# PIC32CX1025SG60100 register map
Vendor: Microchip Technology; Series: PIC32CXSG60; File version: 0
CPU: CM4 r0p1, selectable endian, MPU, FPU, 3 interrupt priority bits, 137 interrupts
Registers are 32-bit, read-write, reset 0x0 unless marked. A register's access mark holds for its fields unless they carry their own. Offsets are from the block's base; [hi:lo] are bit positions; {n}, {i} and the like mark numbered series; 'fields as' and 'values as' point back to an identical list.

## FPU — Floating Point Unit
Base 0xE000EF30
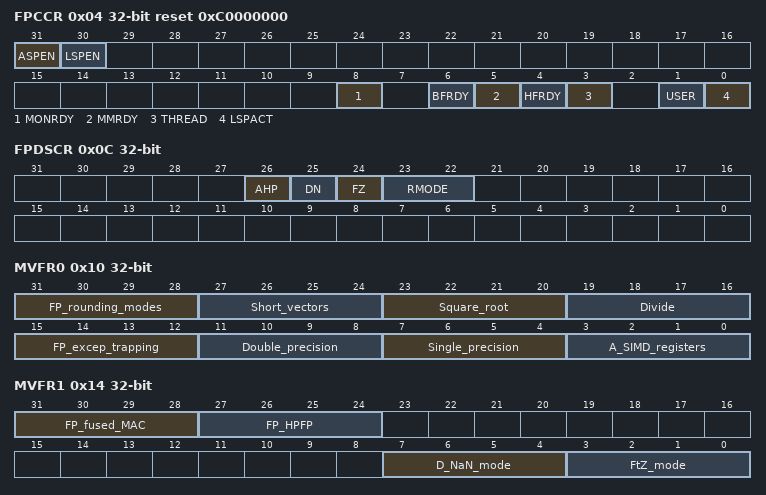
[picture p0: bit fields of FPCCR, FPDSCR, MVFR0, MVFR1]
0x04 FPCCR reset 0xC0000000 — Floating-Point Context Control Register
  [31] ASPEN, [30] LSPEN, [8] MONRDY, [6] BFRDY, [5] MMRDY, [4] HFRDY, [3] THREAD, [1] USER, [0] LSPACT
0x08 FPCAR — Floating-Point Context Address Register
  [31:3] ADDRESS — Address for FP registers in exception stack frame
0x0C FPDSCR — Floating-Point Default Status Control Register
  [26] AHP — Default value for FPSCR.AHP
  [25] DN — Default value for FPSCR.DN
  [24] FZ — Default value for FPSCR.FZ
  [23:22] RMODE — Default value for FPSCR.RMODE
    0=RN (Round to Nearest); 1=RP (Round towards Positive Infinity); 2=RM (Round towards Negative Infinity); 3=RZ (Round towards Zero)
0x10 MVFR0 ro — Media and FP Feature Register 0
  [31:28] FP_rounding_modes, [27:24] Short_vectors, [23:20] Square_root, [19:16] Divide, [15:12] FP_excep_trapping, [11:8] Double_precision, [7:4] Single_precision, [3:0] A_SIMD_registers
0x14 MVFR1 ro — Media and FP Feature Register 1
  [31:28] FP_fused_MAC, [27:24] FP_HPFP, [7:4] D_NaN_mode, [3:0] FtZ_mode

## ITM — Instrumentation Trace Macrocell
Base 0xE0000000
{0x0+4i} PORT_BYTE_MODE[{i}] (i=0..31) wo — ITM Stimulus Port Registers
  [7:0] PORT
{0x0+4i} PORT_HWORD_MODE[{i}] (i=0..31) wo (alternate view of PORT_BYTE_MODE[{i}]) — ITM Stimulus Port Registers
  [15:0] PORT
{0x0+4i} PORT_WORD_MODE[{i}] (i=0..31) wo (alternate view of PORT_BYTE_MODE[{i}]) — ITM Stimulus Port Registers
  [31:0] PORT
0xE00 TER — ITM Trace Enable Register
0xE40 TPR — ITM Trace Privilege Register
  [3:0] PRIVMASK
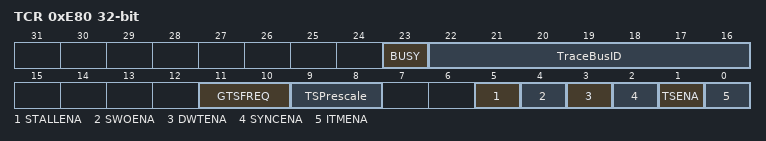
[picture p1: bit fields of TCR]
0xE80 TCR — ITM Trace Control Register
  [23] BUSY, [22:16] TraceBusID, [11:10] GTSFREQ, [9:8] TSPrescale, [5] STALLENA, [4] SWOENA, [3] DWTENA, [2] SYNCENA, [1] TSENA, [0] ITMENA
0xEF8 IWR wo — ITM Integration Write Register
  [0] ATVALIDM
0xEFC IRR ro — ITM Integration Read Register
  [0] ATREADYM
0xFD0 PID4 ro reset 0x4 — ITM Peripheral Identification Register #4
{0xFC0+4i} PID{i} ro (i=5..7) — ITM Peripheral Identification Register #{i}
0xFE0 PID0 ro reset 0x1 — ITM Peripheral Identification Register #0
0xFE4 PID1 ro reset 0xB0 — ITM Peripheral Identification Register #1
0xFE8 PID2 ro reset 0x3B — ITM Peripheral Identification Register #2
0xFEC PID3 ro — ITM Peripheral Identification Register #3
0xFF0 CID0 ro reset 0xD — ITM Component Identification Register #0
0xFF4 CID1 ro reset 0xE0 — ITM Component Identification Register #1
0xFF8 CID2 ro reset 0x5 — ITM Component Identification Register #2
0xFFC CID3 ro reset 0xB1 — ITM Component Identification Register #3

## MPU — Memory Protection Unit
Base 0xE000ED90
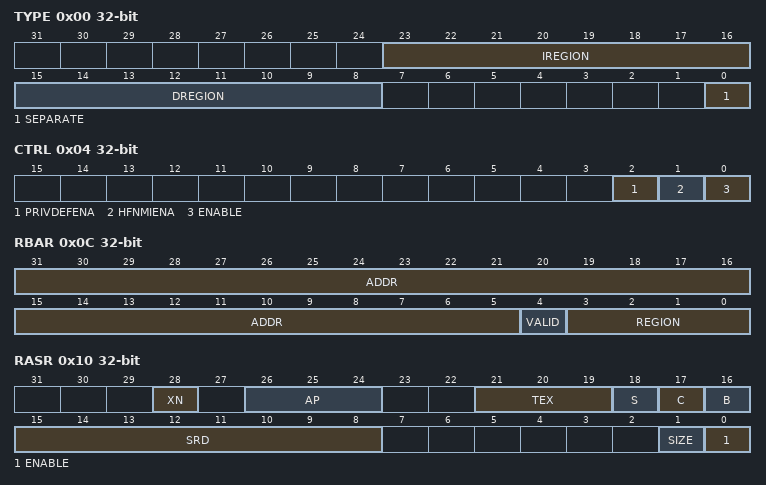
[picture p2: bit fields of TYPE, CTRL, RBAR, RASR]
0x00 TYPE ro — MPU Type Register
  [23:16] IREGION — Number of Instruction Regions
  [15:8] DREGION — Number of Data Regions
  [0] SEPARATE — Separate instruction and Data Memory MapsRegions
0x04 CTRL — MPU Control Register
  [2] PRIVDEFENA — Enables privileged software access to default memory map
  [1] HFNMIENA — Enable Hard Fault and NMI handlers
  [0] ENABLE — MPU Enable
0x08 RNR — MPU Region Number Register
  [7:0] REGION — Region referenced by RBAR and RASR
0x0C RBAR — MPU Region Base Address Register
  [31:5] ADDR — Region base address
  [4] VALID — Region number valid
  [3:0] REGION — Region number
0x10 RASR — MPU Region Attribute and Size Register
  [28] XN — Execute Never Attribute
  [26:24] AP — Access Permission
  [21:19] TEX — TEX bit
  [18] S — Shareable bit
  [17] C — Cacheable bit
  [16] B — Bufferable bit
  [15:8] SRD — Sub-region disable
  [1] SIZE — Region Size
  [0] ENABLE — Region Enable
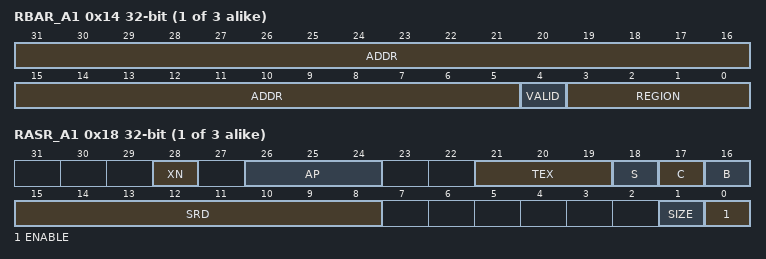
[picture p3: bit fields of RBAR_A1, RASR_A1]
{0xC+8i} RBAR_A{i} (i=1..3) — MPU Alias {i} Region Base Address Register
  fields as RBAR
{0x10+8i} RASR_A{i} (i=1..3) — MPU Alias {i} Region Attribute and Size Register
  fields as RASR

## NVIC — Nested Vectored Interrupt Controller
Base 0xE000E100
{0x0+4i} ISER[{i}] (i=0..4) — Interrupt Set Enable Register
  [31:0] SETENA — Interrupt set enable bits
{0x80+4i} ICER[{i}] (i=0..4) — Interrupt Clear Enable Register
  [31:0] CLRENA — Interrupt clear-enable bits
{0x100+4i} ISPR[{i}] (i=0..4) — Interrupt Set Pending Register
  [31:0] SETPEND — Interrupt set-pending bits
{0x180+4i} ICPR[{i}] (i=0..4) — Interrupt Clear Pending Register
  [31:0] CLRPEND — Interrupt clear-pending bits
{0x200+4i} IABR[{i}] (i=0..4) — Interrupt Active Bit Register
  [31:0] ACTIVE — Interrupt active bits
{0x300+i} IP[{i}] (i=0..34) 8-bit — Interrupt Priority Register n
  [2:0] PRI0 — Priority of interrupt n
0xE00 STIR wo — Software Trigger Interrupt Register
  [8:0] INTID — Interrupt ID to trigger

## SysTick — System timer
Base 0xE000E010
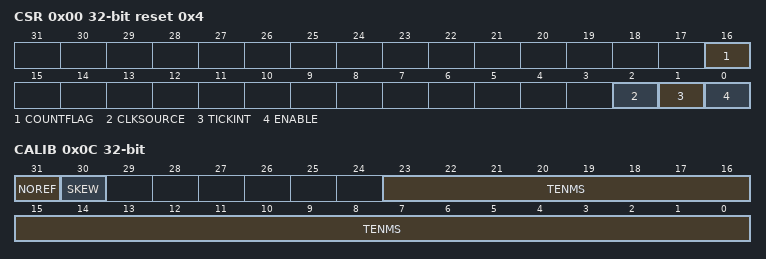
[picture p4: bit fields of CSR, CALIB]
0x00 CSR reset 0x4 — SysTick Control and Status Register
  [16] COUNTFLAG — Timer counted to 0 since last read of register
  [2] CLKSOURCE — Clock Source 0=external, 1=processor
    0=External clock; 1=Processor clock
  [1] TICKINT — SysTick Exception Request Enable
    0=Counting down to 0 does not assert the SysTick exception request; 1=Counting down to 0 asserts the SysTick exception request
  [0] ENABLE — SysTick Counter Enable
    0=Counter disabled; 1=Counter enabled
0x04 RVR — SysTick Reload Value Register
  [23:0] RELOAD — Value to load into the SysTick Current Value Register when the counter reaches 0
0x08 CVR — SysTick Current Value Register
  [23:0] CURRENT — Current value at the time the register is accessed
0x0C CALIB ro — SysTick Calibration Value Register
  [31] NOREF — No Separate Reference Clock
    0=The reference clock is provided; 1=The reference clock is not provided
  [30] SKEW — TENMS is rounded from non-integer ratio
    0=10ms calibration value is exact; 1=10ms calibration value is inexact, because of the clock frequency
  [23:0] TENMS — Reload value to use for 10ms timing

## TPIU — Trace Port Interface Unit
Base 0xE0040000
0x00 SSPSR ro — Supported Parallel Port Size Register
0x04 CSPSR — Current Parallel Port Size Register
0x10 ACPR — Asynchronous Clock Prescaler Register
  [12:0] PRESCALER
0xF0 SPPR — Selected Pin Protocol Register
  [1:0] TXMODE
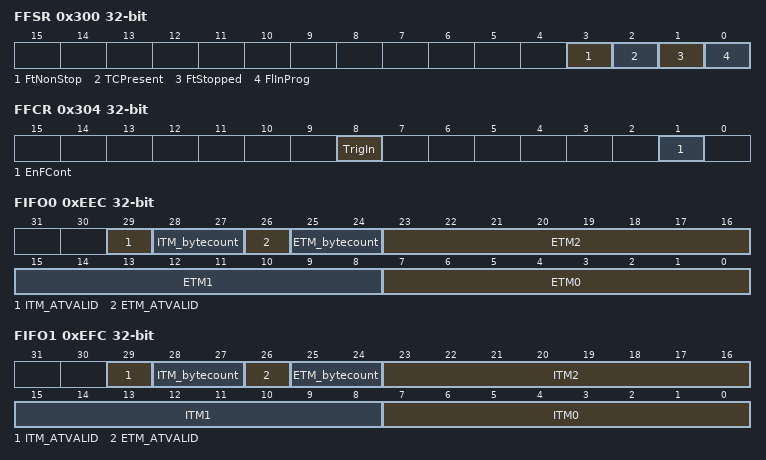
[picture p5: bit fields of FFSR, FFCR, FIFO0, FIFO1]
0x300 FFSR ro — Formatter and Flush Status Register
  [3] FtNonStop, [2] TCPresent, [1] FtStopped, [0] FlInProg
0x304 FFCR — Formatter and Flush Control Register
  [8] TrigIn, [1] EnFCont
0x308 FSCR ro — Formatter Synchronization Counter Register
0xEE8 TRIGGER ro
  [0] TRIGGER
0xEEC FIFO0 ro — Integration ETM Data
  [29] ITM_ATVALID, [28:27] ITM_bytecount, [26] ETM_ATVALID, [25:24] ETM_bytecount, [23:16] ETM2, [15:8] ETM1, [7:0] ETM0
0xEF0 ITATBCTR2 ro
  [0] ATREADY
0xEF8 ITATBCTR0 ro
  [0] ATREADY
0xEFC FIFO1 ro — Integration ITM Data
  [29] ITM_ATVALID, [28:27] ITM_bytecount, [26] ETM_ATVALID, [25:24] ETM_bytecount, [23:16] ITM2, [15:8] ITM1, [7:0] ITM0
0xF00 ITCTRL — Integration Mode Control
  [0] Mode
0xFA0 CLAIMSET — Claim tag set
0xFA4 CLAIMCLR — Claim tag clear
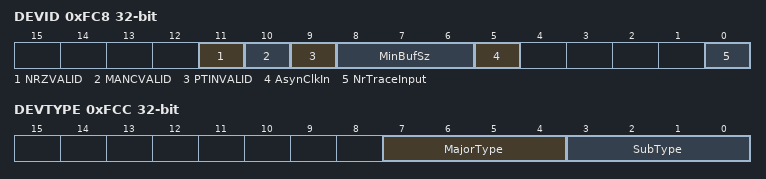
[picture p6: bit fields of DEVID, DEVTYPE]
0xFC8 DEVID ro — TPIU_DEVID
  [11] NRZVALID, [10] MANCVALID, [9] PTINVALID, [8:6] MinBufSz, [5] AsynClkIn, [0] NrTraceInput
0xFCC DEVTYPE ro — TPIU_DEVTYPE
  [7:4] MajorType, [3:0] SubType
